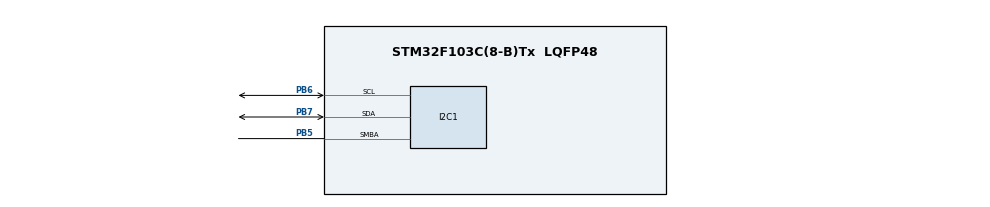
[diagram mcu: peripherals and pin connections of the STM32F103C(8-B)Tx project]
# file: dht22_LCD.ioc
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Mcu.Family=STM32F1
Mcu.Name=STM32F103C(8-B)Tx
Mcu.Package=LQFP48
NVIC.PriorityGroup=NVIC_PRIORITYGROUP_4
PB5.Mode=SMBus-Alert-mode
PB5.Signal=I2C1_SMBA
PB6.Mode=SMBus-Alert-mode
PB6.Signal=I2C1_SCL
PB7.Mode=SMBus-Alert-mode
PB7.Signal=I2C1_SDA
ProjectManager.HeapSize=0x200
ProjectManager.StackSize=0x400
ProjectManager.TargetToolchain=STM32CubeIDE
RCC.APB1Freq_Value=8000000
RCC.APB2Freq_Value=8000000
VP_SYS_VS_ND.Mode=No_Debug
board=custom

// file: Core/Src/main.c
/* USER CODE BEGIN Header */
/**
  ******************************************************************************
  * @file           : main.c
  * @brief          : Main program body
  ******************************************************************************
  */
/* USER CODE END Header */
#include "main.h"

/* USER CODE BEGIN Includes */
#include "ssd1306.h"
#include "fonts.h"
#include "dht22.h"
#include <stdio.h>
/* USER CODE END Includes */

/* USER CODE BEGIN PV */
float temperature, humidity;
char buf[32];
/* USER CODE END PV */

void SystemClock_Config(void);
static void MX_GPIO_Init(void);
static void MX_I2C1_SMBUS_Init(void);

int main(void)
{

  /* MCU Configuration--------------------------------------------------------*/

  /* Reset of all peripherals, Initializes the Flash interface and the Systick. */
  HAL_Init();

  /* Configure the system clock */
  SystemClock_Config();

  /* Initialize all configured peripherals */
  MX_GPIO_Init();
  MX_I2C1_SMBUS_Init();
  /* USER CODE BEGIN 2 */
  HAL_TIM_Base_Start(&htim1);

  ssd1306_Init();
  DHT22_Init(GPIOA, GPIO_PIN_1);
  /* USER CODE END 2 */

  /* Infinite loop */
  /* USER CODE BEGIN WHILE */

    if (DHT22_Read(&temperature, &humidity))
    {
      ssd1306_Fill(Black);
      ssd1306_SetCursor(0, 0);

      sprintf(buf, "Temp: %.1f C", temperature);
      ssd1306_WriteString(buf, Font_7x10, White);

      ssd1306_SetCursor(0, 16);
      sprintf(buf, "Hum : %.1f %%", humidity);
      ssd1306_WriteString(buf, Font_7x10, White);

      ssd1306_UpdateScreen();
    }

    HAL_Delay(2000);
    /* USER CODE END WHILE */

  }
}

void SystemClock_Config(void)
{
  RCC_OscInitTypeDef RCC_OscInitStruct = {0};
  RCC_ClkInitTypeDef RCC_ClkInitStruct = {0};

  /** Initializes the RCC Oscillators according to the specified parameters
  * in the RCC_OscInitTypeDef structure.
  */
  RCC_OscInitStruct.OscillatorType = RCC_OSCILLATORTYPE_HSI;
  RCC_OscInitStruct.HSIState = RCC_HSI_ON;
  RCC_OscInitStruct.HSICalibrationValue = RCC_HSICALIBRATION_DEFAULT;
  RCC_OscInitStruct.PLL.PLLState = RCC_PLL_NONE;
  if (HAL_RCC_OscConfig(&RCC_OscInitStruct) != HAL_OK)
  {
    Error_Handler();
  }

  /** Initializes the CPU, AHB and APB buses clocks
  */
  RCC_ClkInitStruct.ClockType = RCC_CLOCKTYPE_HCLK|RCC_CLOCKTYPE_SYSCLK
                              |RCC_CLOCKTYPE_PCLK1|RCC_CLOCKTYPE_PCLK2;
  RCC_ClkInitStruct.SYSCLKSource = RCC_SYSCLKSOURCE_HSI;
  RCC_ClkInitStruct.AHBCLKDivider = RCC_SYSCLK_DIV1;
  RCC_ClkInitStruct.APB1CLKDivider = RCC_HCLK_DIV1;
  RCC_ClkInitStruct.APB2CLKDivider = RCC_HCLK_DIV1;

  if (HAL_RCC_ClockConfig(&RCC_ClkInitStruct, FLASH_LATENCY_0) != HAL_OK)
  {
    Error_Handler();
  }
}

static void MX_I2C1_SMBUS_Init(void)
{

}

static void MX_GPIO_Init(void)
{

  /* GPIO Ports Clock Enable */
  __HAL_RCC_GPIOB_CLK_ENABLE();

}

void Error_Handler(void)
{
  __disable_irq();
  while (1)
  {
  }
}
